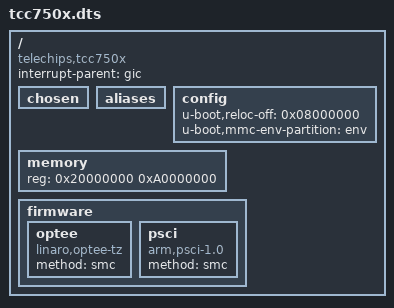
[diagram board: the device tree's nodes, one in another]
// SPDX-License-Identifier: (GPL-2.0-or-later OR MIT)
/*
 * Copyright (C) 2023 Telechips Inc.
 */

/ {
	compatible = "telechips,tcc750x";
	interrupt-parent = <&gic>;
	#address-cells = <1>;
	#size-cells = <1>;

	chosen: chosen {};
	aliases: aliases {};

	config: config {
		u-boot,reloc-off = <0x08000000>;
		u-boot,mmc-env-partition = "env";
	};

	memory: memory {
		device_type = "memory";
		reg = <0x20000000 0xA0000000>;
	};

	firmware: firmware {
		optee: optee {
			compatible = "linaro,optee-tz";
			method = "smc";
		};

		psci: psci {
			compatible = "arm,psci-1.0";
			method = "smc";
		};
	};
};

#include "tcc750x-cpu.dtsi"
#include "tcc750x-clk.dtsi"
#include "tcc750x-gpio.dtsi"
#include "tcc750x-uart.dtsi"
#include "tcc750x-mmc.dtsi"
#include "tcc750x-timer.dtsi"
#include "tcc750x-spi.dtsi"
#include "tcc750x-i2c.dtsi"
#include "tcc750x-pcie.dtsi"
#include "tcc750x-hsmfw.dtsi"
#include "tcc750x-gmac.dtsi"
